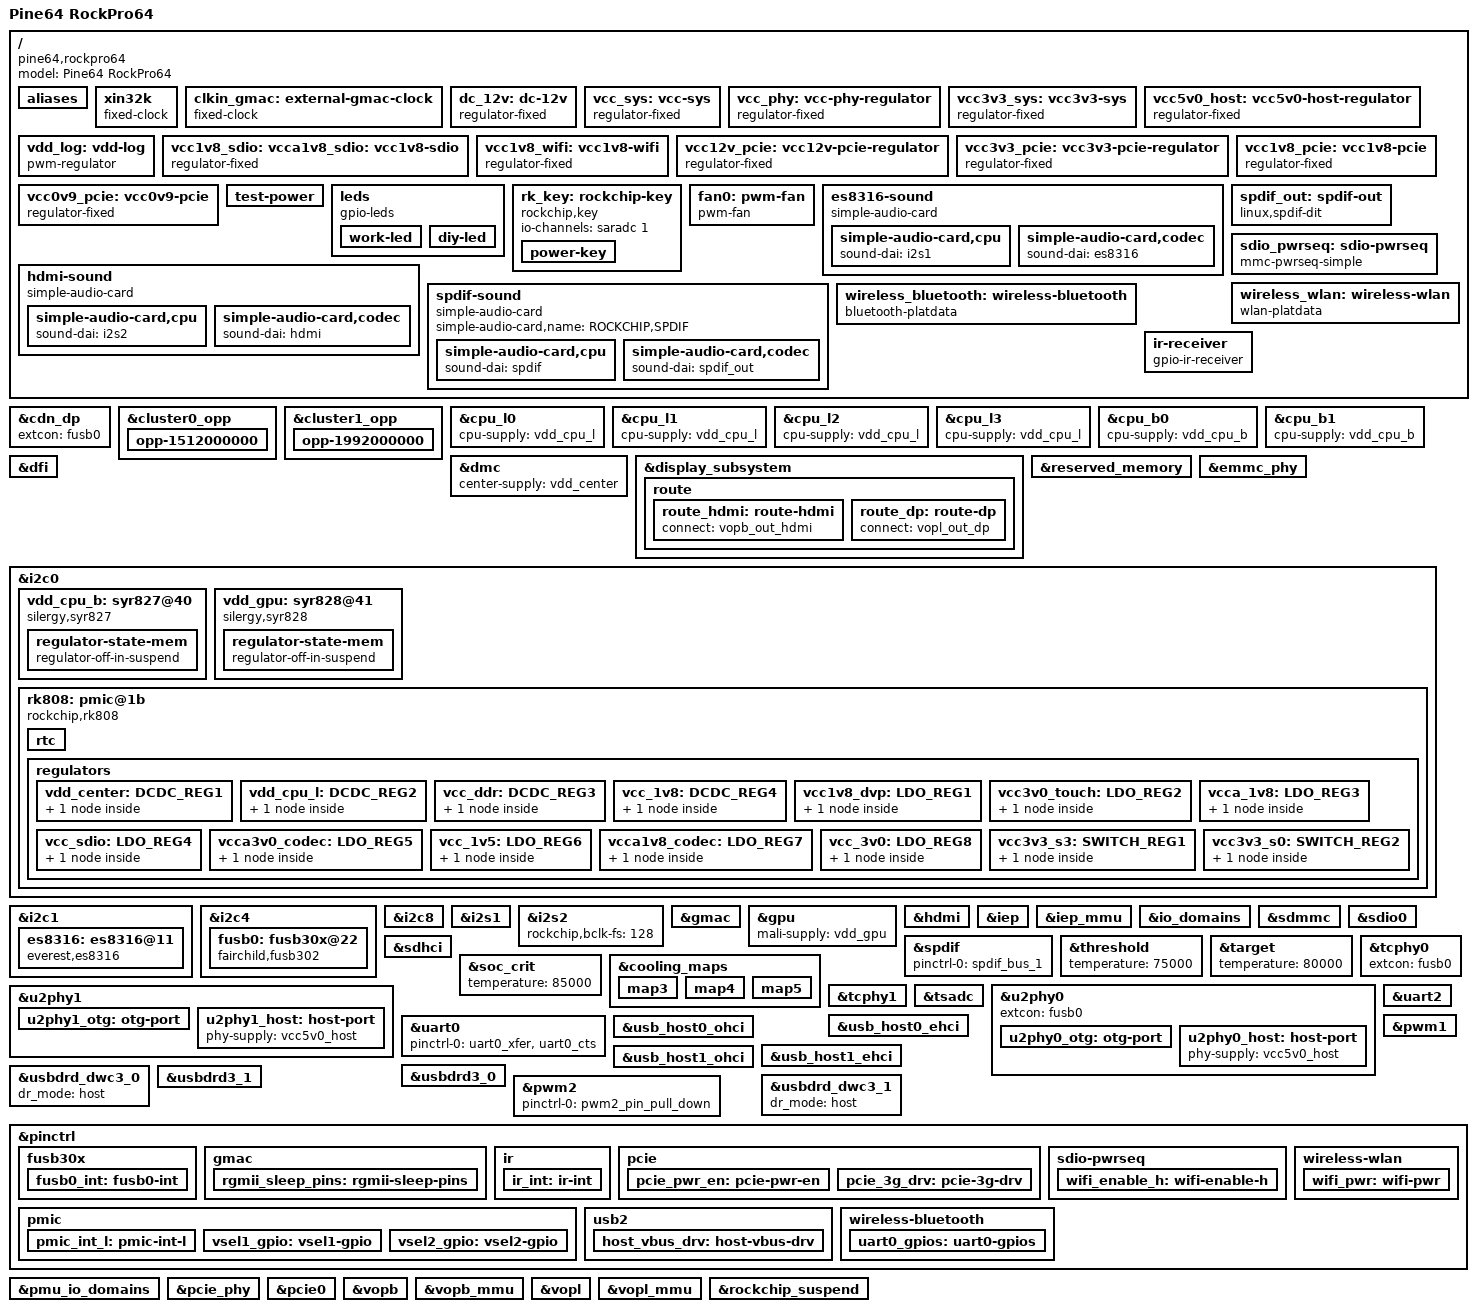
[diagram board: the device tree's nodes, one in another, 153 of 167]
// SPDX-License-Identifier: (GPL-2.0+ OR MIT)
/*
 * Copyright (c) 2018 Pine Microsystems Inc. (PINE64)
 *		Randy Li <ayaka@soulik.info>
 */

/dts-v1/;
#include <dt-bindings/soc/rockchip-io-domain.h>
#include <dt-bindings/pwm/pwm.h>
#include <dt-bindings/input/input.h>
#include "rk3399.dtsi"
#include "rk3399-linux.dtsi"
#include "rk3399-opp.dtsi"

/ {
	model = "Pine64 RockPro64";
	compatible = "pine64,rockpro64", "rockchip,rk3399";

	aliases {
		ethernet0 = &gmac;
		uart0 = &uart0;
	};

	xin32k: xin32k {
		compatible = "fixed-clock";
		clock-frequency = <32768>;
		clock-output-names = "xin32k";
		#clock-cells = <0>;
	};

	clkin_gmac: external-gmac-clock {
		compatible = "fixed-clock";
		clock-frequency = <125000000>;
		clock-output-names = "clkin_gmac";
		#clock-cells = <0>;
	};

	dc_12v: dc-12v {
		compatible = "regulator-fixed";
		regulator-name = "dc_12v";
		regulator-always-on;
		regulator-boot-on;
		regulator-min-microvolt = <12000000>;
		regulator-max-microvolt = <12000000>;
	};

	vcc_sys: vcc-sys {
		compatible = "regulator-fixed";
		regulator-name = "vcc_sys";
		regulator-min-microvolt = <5000000>;
		regulator-max-microvolt = <5000000>;
		regulator-always-on;
		vin-supply = <&dc_12v>;
	};

	vcc_phy: vcc-phy-regulator {
		compatible = "regulator-fixed";
		regulator-name = "vcc_phy";
		regulator-always-on;
		regulator-boot-on;
	};

	vcc3v3_sys: vcc3v3-sys {
		compatible = "regulator-fixed";
		regulator-name = "vcc3v3_sys";
		regulator-min-microvolt = <3300000>;
		regulator-max-microvolt = <3300000>;
		regulator-always-on;
		vin-supply = <&vcc_sys>;
	};

	vcc5v0_host: vcc5v0-host-regulator {
		compatible = "regulator-fixed";
		enable-active-high;
		gpio = <&gpio4 RK_PD2 GPIO_ACTIVE_HIGH>;
		pinctrl-names = "default";
		pinctrl-0 = <&host_vbus_drv>;
		regulator-name = "vcc5v0_host";
		regulator-always-on;
	};

	vdd_log: vdd-log {
		compatible = "pwm-regulator";
		pwms = <&pwm2 0 25000 1>;
		pwm-supply = <&vcc_sys>;
		regulator-name = "vdd_log";
		regulator-min-microvolt = <800000>;
		regulator-max-microvolt = <1400000>;
		regulator-always-on;
		regulator-boot-on;

		/* for rockchip boot on */
		rockchip,pwm_id= <2>;
		rockchip,pwm_voltage = <900000>;
	};

	vcc1v8_sdio: vcca1v8_sdio: vcc1v8-sdio {
		compatible = "regulator-fixed";
		regulator-name = "vcc1v8_sdio";
		regulator-always-on;
		regulator-boot-on;
		regulator-min-microvolt = <1800000>;
		regulator-max-microvolt = <1800000>;
		vin-supply = <&vcc_1v8>;
	};

	vcc1v8_wifi: vcc1v8-wifi {
		compatible = "regulator-fixed";
		enable-active-high;
		gpios = <&gpio0 RK_PB5 GPIO_ACTIVE_HIGH>; 
		pinctrl-names = "default";
		pinctrl-0 = <&wifi_pwr>;
		regulator-name = "vcc1v8_wifi";
		regulator-boot-on;
		vin-supply = <&vcc_1v8>;
	};

	vcc12v_pcie: vcc12v-pcie-regulator {
		compatible = "regulator-fixed";
		regulator-min-microvolt = <12000000>;
		regulator-max-microvolt = <12000000>;
		enable-active-high;
		gpio = <&gpio1 RK_PD0 GPIO_ACTIVE_HIGH>;
		pinctrl-names = "default";
		pinctrl-0 = <&pcie_pwr_en>;
		regulator-name = "vcc12v_pcie";
		regulator-always-on;
		regulator-boot-on;
		vin-supply = <&dc_12v>;
	};

	vcc3v3_pcie: vcc3v3-pcie-regulator {
		compatible = "regulator-fixed";
		regulator-name = "vcc3v3_pcie";
		regulator-min-microvolt = <3300000>;
		regulator-max-microvolt = <3300000>;
		enable-active-high;
		//regulator-always-on;
		regulator-boot-on;
		vin-supply = <&vcc3v3_sys>;
	};

	vcc1v8_pcie: vcc1v8-pcie {
		compatible = "regulator-fixed";
		regulator-name = "vcc1v8_pcie";
		regulator-min-microvolt = <1800000>;
		regulator-max-microvolt = <1800000>;
		//regulator-always-on;
		regulator-boot-on;
		vin-supply = <&vcca_1v8>;
	};

	vcc0v9_pcie: vcc0v9-pcie {
		compatible = "regulator-fixed";
		regulator-name = "vcc0v9_pcie";
		regulator-min-microvolt = <900000>;
		regulator-max-microvolt = <900000>;
		//regulator-always-on;
		regulator-boot-on;
		vin-supply = <&vcc3v3_sys>;
	};

	test-power {
		status = "okay";
	};

	leds {
		compatible = "gpio-leds";

		work-led {
			gpios = <&gpio0 RK_PB3 GPIO_ACTIVE_HIGH>;
			linux,default-trigger = "heartbeat";
			mode = <0x23>;
		};

		diy-led {
			gpios = <&gpio0 RK_PA2 GPIO_ACTIVE_HIGH>;
			linux,default-trigger = "disk-activity";
			mode = <0x23>;
		};
	};

	rk_key: rockchip-key {
		compatible = "rockchip,key";
		status = "okay";

		io-channels = <&saradc 1>;

		power-key {
			gpios = <&gpio0 RK_PA5 GPIO_ACTIVE_LOW>;
			linux,code = <116>;
			label = "power";
			gpio-key,wakeup;
		};
	};

	fan0: pwm-fan {
		compatible = "pwm-fan";
		pwms = <&pwm1 0 10000 0>;
		cooling-min-state = <0>;
		cooling-max-state = <3>;
		#cooling-cells = <2>;
		cooling-levels = <0 80 170 230>;
	}; 

	es8316-sound {
		compatible = "simple-audio-card";
		simple-audio-card,format = "i2s";
		simple-audio-card,name = "ES8316";
		simple-audio-card,mclk-fs = <256>;
		simple-audio-card,widgets =
			"Microphone", "Mic Jack",
			"Headphone", "Headphone Jack";
		simple-audio-card,routing =
			"Headphone Jack", "HPOL",
			"Headphone Jack", "HPOR",
			"Mic Jack", "MIC1";
		simple-audio-card,cpu {
			sound-dai = <&i2s1>;
		};
		simple-audio-card,codec {
			sound-dai = <&es8316>;
		};
	};

	hdmi-sound {
		compatible = "simple-audio-card";
		simple-audio-card,format = "i2s";
		simple-audio-card,mclk-fs = <256>;
		simple-audio-card,name = "HDMI";
		simple-audio-card,cpu {
			sound-dai = <&i2s2>;
		};
		simple-audio-card,codec {
			sound-dai = <&hdmi>;
		};
	};

	spdif-sound {
		status = "okay";
		compatible = "simple-audio-card";
		simple-audio-card,name = "ROCKCHIP,SPDIF";
		simple-audio-card,cpu {
			sound-dai = <&spdif>;
		};
		simple-audio-card,codec {
			sound-dai = <&spdif_out>;
		};
	};

	spdif_out: spdif-out {
		compatible = "linux,spdif-dit";
		#sound-dai-cells = <0>;
		status = "okay";
	};

	sdio_pwrseq: sdio-pwrseq {
		compatible = "mmc-pwrseq-simple";
		clocks = <&rk808 1>;
		clock-names = "ext_clock";
		pinctrl-names = "default";
		pinctrl-0 = <&wifi_enable_h>;

		/*
		 * On the module itself this is one of these (depending
		 * on the actual card populated):
		 * - SDIO_RESET_L_WL_REG_ON
		 * - PDN (power down when low)
		 */
		reset-gpios = <&gpio0 RK_PB2 GPIO_ACTIVE_LOW>;
	};

	wireless_wlan: wireless-wlan {
		compatible = "wlan-platdata";
		rockchip,grf = <&grf>;
		wifi_chip_type = "ap6359sa";
		sdio_vref = <1800>;
		WIFI,host_wake_irq = <&gpio0 RK_PA3 GPIO_ACTIVE_HIGH>;
		status = "okay";
	};

	wireless_bluetooth: wireless-bluetooth {
		compatible = "bluetooth-platdata";
		clocks = <&rk808 1>;
		clock-names = "ext_clock";
		uart_rts_gpios = <&gpio2 RK_PC3 GPIO_ACTIVE_LOW>;
		pinctrl-names = "default", "rts_gpio";
		pinctrl-0 = <&uart0_rts>;
		pinctrl-1 = <&uart0_gpios>;
		BT,reset_gpio    = <&gpio0 RK_PB1 GPIO_ACTIVE_HIGH>;
		BT,wake_gpio     = <&gpio2 RK_PD3 GPIO_ACTIVE_HIGH>;
		BT,wake_host_irq = <&gpio0 RK_PA4 GPIO_ACTIVE_HIGH>;
		status = "okay";
	};

	ir-receiver {
		compatible = "gpio-ir-receiver";
		gpios = <&gpio0 RK_PA6 GPIO_ACTIVE_LOW>;
		pinctrl-names = "default";
		pinctrl-0 = <&ir_int>;
	};
};

&cdn_dp {
	status = "okay";
	extcon = <&fusb0>;
};


&cluster0_opp {
	opp-1512000000 {
		opp-hz = /bits/ 64 <1512000000>;
		opp-microvolt = <1200000 1200000 1250000>;
		opp-microvolt-L0 = <1200000 1200000 1250000>;
		opp-microvolt-L1 = <1175000 1175000 1250000>;
		opp-microvolt-L2 = <1150000 1150000 1250000>;
		opp-microvolt-L3 = <1125000 1125000 1250000>;
		clock-latency-ns = <40000>;
	};
};

&cluster1_opp {
	opp-1992000000 {
		opp-hz = /bits/ 64 <1992000000>;
		opp-microvolt = <1300000 1300000 1300000>;
		opp-microvolt-L0 = <1300000 1300000 1300000>;
		opp-microvolt-L1 = <1275000 1275000 1300000>;
		opp-microvolt-L2 = <1250000 1250000 1300000>;
		opp-microvolt-L3 = <1225000 1225000 1300000>;
		opp-microvolt-L4 = <1225000 1225000 1300000>;
		clock-latency-ns = <40000>;
	};
};


&cpu_l0 {
	cpu-supply = <&vdd_cpu_l>;
};

&cpu_l1 {
	cpu-supply = <&vdd_cpu_l>;
};

&cpu_l2 {
	cpu-supply = <&vdd_cpu_l>;
};

&cpu_l3 {
	cpu-supply = <&vdd_cpu_l>;
};

&cpu_b0 {
	cpu-supply = <&vdd_cpu_b>;
};

&cpu_b1 {
	cpu-supply = <&vdd_cpu_b>;
};

&dfi {
	status = "okay";
};

&dmc {
	status = "okay";
	center-supply = <&vdd_center>;
};

&display_subsystem {
	status = "okay";
	/delete-property/ logo-memory-region;

	route {
		route_hdmi: route-hdmi {
			status = "okay";
			connect = <&vopb_out_hdmi>;
		};

		route_dp: route-dp {
			connect = <&vopl_out_dp>;
		};
	};
};

&reserved_memory {
	/delete-node/ drm_logo; 
};

&emmc_phy {
	status = "okay";
};

&i2c0 {
	status = "okay";
	i2c-scl-rising-time-ns = <180>;
	i2c-scl-falling-time-ns = <30>;
	clock-frequency = <400000>;

	vdd_cpu_b: syr827@40 {
		compatible = "silergy,syr827";
		reg = <0x40>;
		regulator-compatible = "fan53555-reg";
		pinctrl-0 = <&vsel1_gpio>;
		vsel-gpios = <&gpio1 RK_PC1 GPIO_ACTIVE_HIGH>;
		regulator-name = "vdd_cpu_b";
		regulator-min-microvolt = <712500>;
		regulator-max-microvolt = <1500000>;
		regulator-ramp-delay = <1000>;
		fcs,suspend-voltage-selector = <1>;
		regulator-always-on;
		regulator-boot-on;
		vin-supply = <&vcc_sys>;
		regulator-state-mem {
			regulator-off-in-suspend;
		};
	};

	vdd_gpu: syr828@41 {
		compatible = "silergy,syr828";
		reg = <0x41>;
		regulator-compatible = "fan53555-reg";
		pinctrl-0 = <&vsel2_gpio>;
		vsel-gpios = <&gpio1 RK_PB6 GPIO_ACTIVE_HIGH>;
		regulator-name = "vdd_gpu";
		regulator-min-microvolt = <712500>;
		regulator-max-microvolt = <1500000>;
		regulator-enable-ramp-delay = <300>;
		regulator-ramp-delay = <1000>;
		fcs,suspend-voltage-selector = <1>;
		regulator-always-on;
		regulator-boot-on;
		vin-supply = <&vcc_sys>;
		regulator-initial-mode = <1>; /* 1:force PWM 2:auto */
		regulator-state-mem {
			regulator-off-in-suspend;
		};
	};

	rk808: pmic@1b {
		compatible = "rockchip,rk808";
		reg = <0x1b>;
		interrupt-parent = <&gpio1>;
		interrupts = <21 IRQ_TYPE_LEVEL_LOW>;
		pinctrl-names = "default";
		pinctrl-0 = <&pmic_int_l>;
		rockchip,system-power-controller;
		wakeup-source;
		#clock-cells = <1>;
		clock-output-names = "rk808-clkout1", "rk808-clkout2";

		vcc1-supply = <&vcc_sys>;
		vcc2-supply = <&vcc_sys>;
		vcc3-supply = <&vcc_sys>;
		vcc4-supply = <&vcc_sys>;
		vcc6-supply = <&vcc_sys>;
		vcc7-supply = <&vcc_sys>;
		vcc8-supply = <&vcc3v3_sys>;
		vcc9-supply = <&vcc_sys>;
		vcc10-supply = <&vcc_sys>;
		vcc11-supply = <&vcc_sys>;
		vcc12-supply = <&vcc3v3_sys>;
		vddio-supply = <&vcc_1v8>;

		rtc {
			status = "okay";
		};

		regulators {
			vdd_center: DCDC_REG1 {
				regulator-name = "vdd_center";
				regulator-min-microvolt = <900000>;
				regulator-max-microvolt = <900000>;
				regulator-ramp-delay = <6001>;
				regulator-always-on;
				regulator-boot-on;
				regulator-state-mem {
					regulator-off-in-suspend;
				};
			};

			vdd_cpu_l: DCDC_REG2 {
				regulator-name = "vdd_cpu_l";
				regulator-min-microvolt = <750000>;
				regulator-max-microvolt = <1350000>;
				regulator-ramp-delay = <6001>;
				regulator-always-on;
				regulator-boot-on;
				regulator-state-mem {
					regulator-off-in-suspend;
				};
			};

			vcc_ddr: DCDC_REG3 {
				regulator-name = "vcc_ddr";
				regulator-always-on;
				regulator-boot-on;
				regulator-state-mem {
					regulator-on-in-suspend;
				};
			};

			vcc_1v8: DCDC_REG4 {
				regulator-name = "vcc_1v8";
				regulator-min-microvolt = <1800000>;
				regulator-max-microvolt = <1800000>;
				regulator-always-on;
				regulator-boot-on;
				regulator-state-mem {
					regulator-on-in-suspend;
					regulator-suspend-microvolt = <1800000>;
				};
			};

			vcc1v8_dvp: LDO_REG1 {
				regulator-name = "vcc1v8_dvp";
				regulator-min-microvolt = <1800000>;
				regulator-max-microvolt = <1800000>;
				regulator-always-on;
				regulator-boot-on;
				regulator-state-mem {
					regulator-on-in-suspend;
					regulator-suspend-microvolt = <1800000>;
				};
			};

			vcc3v0_touch: LDO_REG2 {
				regulator-name = "vcc3v0_touch";
				regulator-min-microvolt = <3000000>;
				regulator-max-microvolt = <3000000>;
				regulator-always-on;
				regulator-boot-on;
				regulator-state-mem {
					regulator-on-in-suspend;
					regulator-suspend-microvolt = <3000000>;
				};
			};

			vcca_1v8: LDO_REG3 {
				regulator-name = "vcca_1v8";
				regulator-min-microvolt = <1800000>;
				regulator-max-microvolt = <1800000>;
				regulator-always-on;
				regulator-boot-on;
				regulator-state-mem {
					regulator-on-in-suspend;
					regulator-suspend-microvolt = <1800000>;
				};
			};

			vcc_sdio: LDO_REG4 {
				regulator-name = "vcc_sdio";
				regulator-min-microvolt = <1800000>;
				regulator-max-microvolt = <3000000>;
				regulator-always-on;
				regulator-boot-on;
				regulator-state-mem {
					regulator-on-in-suspend;
					regulator-suspend-microvolt = <3000000>;
				};
			};

			vcca3v0_codec: LDO_REG5 {
				regulator-name = "vcca3v0_codec";
				regulator-min-microvolt = <3000000>;
				regulator-max-microvolt = <3000000>;
				regulator-always-on;
				regulator-boot-on;
				regulator-state-mem {
					regulator-on-in-suspend;
					regulator-suspend-microvolt = <3000000>;
				};
			};

			vcc_1v5: LDO_REG6 {
				regulator-name = "vcc_1v5";
				regulator-min-microvolt = <1500000>;
				regulator-max-microvolt = <1500000>;
				regulator-always-on;
				regulator-boot-on;
				regulator-state-mem {
					regulator-on-in-suspend;
					regulator-suspend-microvolt = <1500000>;
				};
			};

			vcca1v8_codec: LDO_REG7 {
				regulator-name = "vcca1v8_codec";
				regulator-min-microvolt = <1800000>;
				regulator-max-microvolt = <1800000>;
				regulator-always-on;
				regulator-boot-on;
				regulator-state-mem {
					regulator-on-in-suspend;
					regulator-suspend-microvolt = <1800000>;
				};
			};

			vcc_3v0: LDO_REG8 {
				regulator-name = "vcc_3v0";
				regulator-min-microvolt = <3000000>;
				regulator-max-microvolt = <3000000>;
				regulator-always-on;
				regulator-boot-on;
				regulator-state-mem {
					regulator-on-in-suspend;
					regulator-suspend-microvolt = <3000000>;
				};
			};

			vcc3v3_s3: SWITCH_REG1 {
				regulator-name = "vcc3v3_s3";
				regulator-always-on;
				regulator-boot-on;
				regulator-state-mem {
					regulator-on-in-suspend;
				};
			};

			vcc3v3_s0: SWITCH_REG2 {
				regulator-name = "vcc3v3_s0";
				regulator-always-on;
				regulator-boot-on;
				regulator-state-mem {
					regulator-on-in-suspend;
				};
			};
		};
	};
};

&i2c1 {
	status = "okay";
	i2c-scl-rising-time-ns = <168>;
	i2c-scl-falling-time-ns = <4>;

	es8316: es8316@11 {
		#sound-dai-cells = <0>;
		compatible = "everest,es8316";
		reg = <0x11>;
		clocks = <&cru SCLK_I2S_8CH_OUT>;
		clock-names = "mclk";
		pinctrl-names = "default";
		pinctrl-0 = <&i2s_8ch_mclk>;
		hp-det-gpio = <&gpio0 RK_PB0 GPIO_ACTIVE_HIGH>;
	};
};

&i2c4 {
	status = "okay";
	fusb0: fusb30x@22 {
		compatible = "fairchild,fusb302";
		reg = <0x22>;
		fusb302,role = "ROLE_MODE_DRP";
		pinctrl-names = "default";
		pinctrl-0 = <&fusb0_int>;
		vbus-5v-gpios = <&gpio1 RK_PA3 GPIO_ACTIVE_HIGH>;
		int-n-gpios = <&gpio1 RK_PA2 GPIO_ACTIVE_HIGH>;
		status = "okay";
	};
};

&i2c8 {
	status = "okay";
};

&i2s1 {
	status = "okay";
	rockchip,i2s-broken-burst-len;
	rockchip,playback-channels = <8>;
	rockchip,capture-channels = <8>;
	#sound-dai-cells = <0>;
};

&i2s2 {
	#sound-dai-cells = <0>;
	rockchip,bclk-fs = <128>;
	status = "okay";
};

&gmac {
	phy-supply = <&vcc_phy>;
	phy-mode = "rgmii";
	clock_in_out = "input";
	rockchip,bugged_tx_coe;
	snps,reset-gpio = <&gpio3 RK_PB7 GPIO_ACTIVE_LOW>;
	snps,reset-active-low;
	snps,reset-delays-us = <0 10000 50000>;
	assigned-clocks = <&cru SCLK_RMII_SRC>;
	assigned-clock-parents = <&clkin_gmac>;
	pinctrl-names = "default", "sleep";
	pinctrl-0 = <&rgmii_pins>;
	pinctrl-1 = <&rgmii_sleep_pins>;
	tx_delay = <0x28>;
	rx_delay = <0x20>;
	status = "okay";
};

&gpu {
	status = "okay";
	mali-supply = <&vdd_gpu>;
};

&hdmi {
	#address-cells = <1>;
	#size-cells = <0>;
	#sound-dai-cells = <0>;
	status = "okay";
	rockchip,phy-table =
		<74250000 0x8009 0x0004 0x0272>,
		<165000000 0x802b 0x0004 0x0209>,
		<297000000 0x8039 0x0005 0x028d>,
		<594000000 0x8039 0x0000 0x019d>,
		<000000000 0x0000 0x0000 0x0000>;
};

&iep {
	status = "okay";
};

&iep_mmu {
	status = "okay";
};

&io_domains {
	status = "okay";
	/*
	 * If the uboot use rkdevelop branch, the io-domain is not set
	 * during uboot phase, it will cause the io voltage is not suit for
	 * the hardware,maybe will damage the io of rk3399, so we add
	 * uboot-set value to make sure the value is same with the kernel,
	 * ofcause you must make sure firstly the value here is suit for your
	 * hardware. The available value is defined in
	 * include/dt-bindings/soc/rockchip-io-domain.h, they are
	 * also list here for more convenient configuration:
	 * bt656-supply: RK3399_BT656_VDD_1V8 or RK3399_BT656_VDD_3V3
	 * audio-supply: RK3399_AUDIO_VDD_1V8 or RK3399_AUDIO_VDD_3V3
	 * gpio1830-supply: RK3399_GPIO1833_VDD_1V8 or RK3399_GPIO1833_VDD_3V3
	 * sdmmc-supply: don't need to configure because the voltage
	 *                       is set in source code during runtime.
	 * NOTE:
	 * 1. The value in uboot-set must be enclosed in "()", otherwise will
	 *     cause compile error.
	 * 2. The uboot-set configuration must be cooperated with submit
	 *     in u-boot.
	 */
	uboot-set = <(RK3399_BT656_VDD_1V8 | RK3399_AUDIO_VDD_1V8 |
				RK3399_GPIO1833_VDD_3V3)>;
	bt656-supply = <&vcc1v8_dvp>; /* bt656_gpio2ab_ms */
	audio-supply = <&vcca3v0_codec>; /* audio_gpio3d4a_ms */
	sdmmc-supply = <&vcc_sdio>; /* sdmmc_gpio4b_ms */
	gpio1830-supply = <&vcc_3v0>; /* gpio1833_gpio4cd_ms */
};

&sdmmc {
	clock-frequency = <50000000>;
	max-frequency = <150000000>;
	supports-sd;
	bus-width = <4>;
	cap-mmc-highspeed;
	cap-sd-highspeed;
	disable-wp;
	num-slots = <1>;
	sd-uhs-sdr12;
	sd-uhs-sdr25;
	sd-uhs-sdr50;
	sd-uhs-sdr104;
	vqmmc-supply = <&vcc_sdio>;
	pinctrl-names = "default";
	pinctrl-0 = <&sdmmc_clk &sdmmc_cmd &sdmmc_cd &sdmmc_bus4>;
	card-detect-delay = <800>;
	status = "okay";
};

&sdio0 {
	clock-frequency = <50000000>;
	max-frequency = <50000000>;
	supports-sdio;
	bus-width = <4>;
	disable-wp;
	cap-sd-highspeed;
	cap-sdio-irq;
	keep-power-in-suspend;
	mmc-pwrseq = <&sdio_pwrseq>;
	non-removable;
	num-slots = <1>;
	pinctrl-names = "default";
	pinctrl-0 = <&sdio0_bus4 &sdio0_cmd &sdio0_clk>;
	sd-uhs-sdr104;
	vqmmc-supply = <&vcc1v8_sdio>;	/* IO line */
	vmmc-supply = <&vcc_sdio>;		/* card's power */
	defer_pcie = <3500>;		/* wait 3500 ms (max) for PCIe driver to load */
	status = "okay";
};

&sdhci {
	bus-width = <8>;
	//mmc-hs400-1_8v;
	//mmc-hs400-enhanced-strobe;
	mmc-hs200-1_8v;
	supports-emmc;
	non-removable;
	keep-power-in-suspend;
	status = "okay";
};

&spdif {
	status = "okay";
	pinctrl-0 = <&spdif_bus_1>;
	#sound-dai-cells = <0>;
};

&threshold {
	temperature = <75000>;
};

&target {
	temperature = <80000>;
};

&soc_crit {
	temperature = <85000>;
};

&cooling_maps {
	map3 {
		trip = <&threshold>;
		cooling-device = <&fan0 0 1>;
		contribution = <4096>;
	};
	map4 {
		trip = <&target>;
		cooling-device = <&fan0 1 2>;
		contribution = <4096>;
	};
	map5 {
		trip = <&soc_crit>;
		cooling-device = <&fan0 2 3>;
		contribution = <4096>;
 	};
 };

&tcphy0 {
	extcon = <&fusb0>;
	status = "okay";
};

&tcphy1 {
	status = "okay";
};

&tsadc {
	/* tshut mode 0:CRU 1:GPIO */
	rockchip,hw-tshut-mode = <1>;
	/* tshut polarity 0:LOW 1:HIGH */
	rockchip,hw-tshut-polarity = <1>;
	rockchip,hw-tshut-temp = <110000>;
	status = "okay";
};

&u2phy0 {
	status = "okay";
	extcon = <&fusb0>;

	u2phy0_otg: otg-port {
		status = "okay";
	};

	u2phy0_host: host-port {
		phy-supply = <&vcc5v0_host>;
		status = "okay";
	};
};

&u2phy1 {
	status = "okay";

	u2phy1_otg: otg-port {
		status = "okay";
	};

	u2phy1_host: host-port {
		phy-supply = <&vcc5v0_host>;
		status = "okay";
	};
};

&uart0 {
	pinctrl-names = "default";
	pinctrl-0 = <&uart0_xfer &uart0_cts>;
	status = "okay";
};

&uart2 {
	status = "okay";
};

&usb_host0_ehci {
	status = "okay";
};

&usb_host0_ohci {
	status = "okay";
};

&usb_host1_ehci {
	status = "okay";
};

&usb_host1_ohci {
	status = "okay";
};

&usbdrd3_0 {
	//extcon = <&fusb0>;
	status = "okay";
};

&usbdrd_dwc3_0 {
	dr_mode = "host";
	status = "okay";
};

&usbdrd3_1 {
	status = "okay";
};

&usbdrd_dwc3_1 {
	dr_mode = "host";
	status = "okay";
};

&pwm1 {
	status = "okay";
};

&pwm2 {
	status = "okay";
	pinctrl-0 = <&pwm2_pin_pull_down>;
};

&pinctrl {
	fusb30x {
		fusb0_int: fusb0-int {
			rockchip,pins =
				<1 RK_PA2 RK_FUNC_GPIO &pcfg_pull_up>;
		};
	};

	gmac {
		rgmii_sleep_pins: rgmii-sleep-pins {
			rockchip,pins =
				<3 RK_PB7 RK_FUNC_GPIO &pcfg_output_low>;
		};
	};

	ir {
		ir_int: ir-int {
			rockchip,pins =
				<0 RK_PA6 RK_FUNC_GPIO &pcfg_pull_none>;
		};
	};

	pcie {
		pcie_pwr_en: pcie-pwr-en {
			rockchip,pins =
				<1 RK_PD0 RK_FUNC_GPIO &pcfg_pull_none>;
		};
		pcie_3g_drv: pcie-3g-drv {
			rockchip,pins =
				<0 RK_PA2 RK_FUNC_GPIO &pcfg_pull_up>;
		};
	};

	pmic {
		pmic_int_l: pmic-int-l {
			rockchip,pins =
				<1 RK_PC5 RK_FUNC_GPIO &pcfg_pull_up>;
		};

		vsel1_gpio: vsel1-gpio {
			rockchip,pins =
				<1 RK_PC1 RK_FUNC_GPIO &pcfg_pull_down>;
		};

		vsel2_gpio: vsel2-gpio {
			rockchip,pins =
				<1 RK_PB6 RK_FUNC_GPIO &pcfg_pull_down>;
		};
	};

	sdio-pwrseq {
		wifi_enable_h: wifi-enable-h {
			rockchip,pins =
				<0 RK_PB2 RK_FUNC_GPIO &pcfg_pull_none>;
		};
	};

	usb2 {
		host_vbus_drv: host-vbus-drv {
			rockchip,pins =
				<4 RK_PD2 RK_FUNC_GPIO &pcfg_pull_none>;
		};
	};

	wireless-wlan {
		wifi_pwr: wifi-pwr {
			rockchip,pins = <0 RK_PB5 RK_FUNC_GPIO &pcfg_pull_none>;
		};
	};

	wireless-bluetooth {
		uart0_gpios: uart0-gpios {
			rockchip,pins =
				<2 RK_PC3 RK_FUNC_1 &pcfg_pull_up>;
		};
	};
};

&pmu_io_domains {
	status = "okay";
	/*
	 * If the uboot use rkdevelop branch, the pmu_io_domain is not set
	 * during uboot phase, it will cause the io voltage is not suit for
	 * the hardware,maybe will damage the io of rk3399, so we add
	 * uboot-set value to make sure the value is same with the kernel,
	 * ofcause you must make sure firstly the value here is suit for your
	 * hardware. The available value is defined in
	 * include/dt-bindings/soc/rockchip-io-domain.h, they are
	 * also list here for more convenient configuration:
	 * pmu1830-supply: RK3399_PMU1830_VDD_1V8 or RK3399_PMU1830_VDD_3V0
	 */
	uboot-set = <RK3399_PMU1830_VDD_3V0>;
	pmu1830-supply = <&vcc_3v0>;
};

&pcie_phy {
	status = "okay";
};

&pcie0 {
	assigned-clocks = <&cru SCLK_PCIEPHY_REF>;
	assigned-clock-parents = <&cru SCLK_PCIEPHY_REF100M>;
	assigned-clock-rates = <100000000>;
	ep-gpios = <&gpio2 RK_PD4 GPIO_ACTIVE_HIGH>;
	num-lanes = <4>;
	max-link-speed = <2>;
	pinctrl-names = "default";
	pinctrl-0 = <&pcie_clkreqn>;
	vpcie12v-supply = <&vcc12v_pcie>;
	vpcie3v3-supply = <&vcc3v3_pcie>;
	vpcie1v8-supply = <&vcc1v8_pcie>;
	vpcie0v9-supply = <&vcc0v9_pcie>;
	status = "okay";
};

&vopb {
	status = "okay";
	assigned-clocks = <&cru DCLK_VOP0_DIV>;
	assigned-clock-parents = <&cru PLL_VPLL>;
};

&vopb_mmu {
	status = "okay";
};

&vopl {
	status = "okay";
	assigned-clocks = <&cru DCLK_VOP1_DIV>;
	assigned-clock-parents = <&cru PLL_CPLL>;
};

&vopl_mmu {
	status = "okay";
};

&rockchip_suspend {
	status = "okay";
	rockchip,sleep-debug-en = <1>;
	rockchip,sleep-mode-config = <
		(0
		| RKPM_SLP_ARMPD
		| RKPM_SLP_PERILPPD
		| RKPM_SLP_DDR_RET
		| RKPM_SLP_PLLPD
		| RKPM_SLP_CENTER_PD
		| RKPM_SLP_AP_PWROFF
		)
	>;
	rockchip,wakeup-config = <
		(0
		| RKPM_GPIO_WKUP_EN
		| RKPM_PWM_WKUP_EN
		)
	>;
	rockchip,pwm-regulator-config = <
		(0
		| PWM2_REGULATOR_EN
		)
	>;
	rockchip,power-ctrl =
		<&gpio1 RK_PC1 GPIO_ACTIVE_HIGH>,
		<&gpio1 RK_PB6 GPIO_ACTIVE_HIGH>;
};
